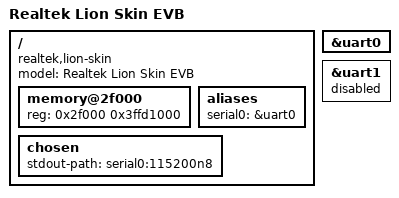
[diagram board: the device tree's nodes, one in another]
/dts-v1/;
#include "rtd1395.dtsi"
/ {
	compatible = "realtek,lion-skin", "realtek,rtd1395";
	model = "Realtek Lion Skin EVB";
	memory@2f000 {
		device_type = "memory";
		reg = <0x2f000 0x3ffd1000>;  
	};
	aliases {
		serial0 = &uart0;
	};
	chosen {
		stdout-path = "serial0:115200n8";
	};
};
&uart0 {
	status = "okay";
};
&uart1 {
	status = "disabled";
};
